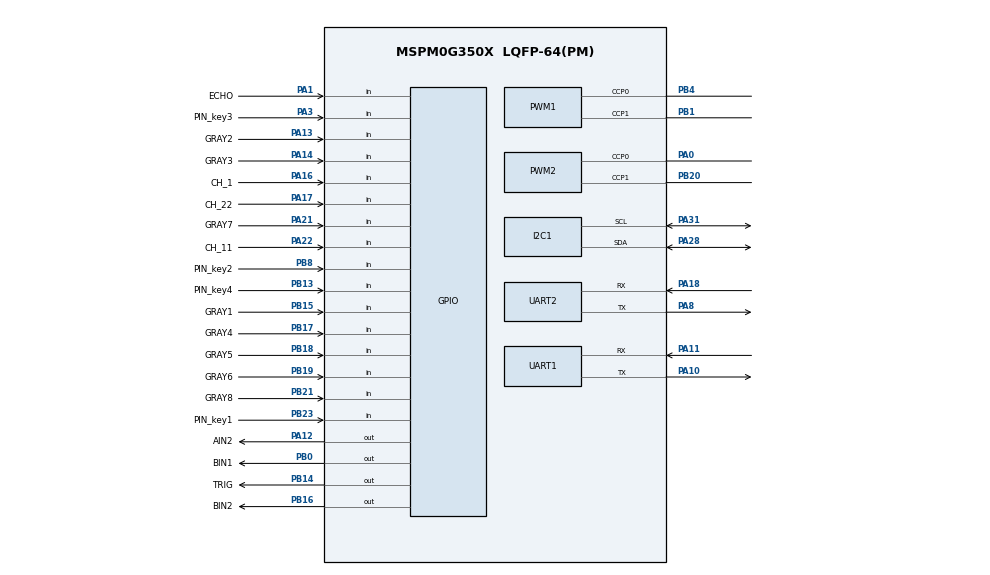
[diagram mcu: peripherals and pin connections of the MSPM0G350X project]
/**
 * @cliArgs --device "MSPM0G350X" --part "Default" --package "LQFP-64(PM)" --product "mspm0_sdk@2.11.00.07"
 * @versions {"tool":"1.26.2+4477"}
 */

/**
 * Import the modules used in this configuration.
 */
const GPIO   = scripting.addModule("/ti/driverlib/GPIO", {}, false);
const GPIO1  = GPIO.addInstance();
const GPIO2  = GPIO.addInstance();
const GPIO3  = GPIO.addInstance();
const GPIO4  = GPIO.addInstance();
const GPIO5  = GPIO.addInstance();
const PWM    = scripting.addModule("/ti/driverlib/PWM", {}, false);
const PWM1   = PWM.addInstance();
const PWM2   = PWM.addInstance();
const SYSCTL = scripting.addModule("/ti/driverlib/SYSCTL");
const TIMER  = scripting.addModule("/ti/driverlib/TIMER", {}, false);
const TIMER1 = TIMER.addInstance();
const TIMER2 = TIMER.addInstance();
const UART   = scripting.addModule("/ti/driverlib/UART", {}, false);
const UART1  = UART.addInstance();
const UART2  = UART.addInstance();

/**
 * Write custom configuration values to the imported modules.
 */
GPIO1.$name                                 = "MOTOR_DIR1";
GPIO1.associatedPins.create(4);
GPIO1.associatedPins[0].$name               = "AIN1";
GPIO1.associatedPins[0].subChanID           = 8;
GPIO1.associatedPins[0].assignedPort        = "PORTB";
GPIO1.associatedPins[0].assignedPin         = "9";
GPIO1.associatedPins[1].$name               = "AIN2";
GPIO1.associatedPins[1].assignedPort        = "PORTA";
GPIO1.associatedPins[1].assignedPin         = "12";
GPIO1.associatedPins[1].pin.$assign         = "PA12";
GPIO1.associatedPins[2].$name               = "CH_1";
GPIO1.associatedPins[2].direction           = "INPUT";
GPIO1.associatedPins[2].interruptEn         = true;
GPIO1.associatedPins[2].internalResistor    = "PULL_DOWN";
GPIO1.associatedPins[2].polarity            = "RISE_FALL";
GPIO1.associatedPins[2].assignedPortSegment = "Upper";
GPIO1.associatedPins[2].assignedPort        = "PORTA";
GPIO1.associatedPins[2].assignedPin         = "16";
GPIO1.associatedPins[2].pin.$assign         = "PA16";
GPIO1.associatedPins[3].$name               = "CH_2";
GPIO1.associatedPins[3].direction           = "INPUT";
GPIO1.associatedPins[3].internalResistor    = "PULL_DOWN";
GPIO1.associatedPins[3].assignedPort        = "PORTA";
GPIO1.associatedPins[3].interruptEn         = true;
GPIO1.associatedPins[3].polarity            = "RISE_FALL";
GPIO1.associatedPins[3].assignedPin         = "15";
GPIO1.associatedPins[3].assignedPortSegment = "Lower";

const Board = scripting.addModule("/ti/driverlib/Board", {}, false);

GPIO2.$name                                 = "MOTOR_DIR2";
GPIO2.associatedPins.create(4);
GPIO2.associatedPins[0].$name               = "BIN1";
GPIO2.associatedPins[0].assignedPort        = "PORTB";
GPIO2.associatedPins[0].assignedPin         = "00";
GPIO2.associatedPins[0].pin.$assign         = "PB0";
GPIO2.associatedPins[1].$name               = "BIN2";
GPIO2.associatedPins[1].assignedPin         = "16";
GPIO2.associatedPins[1].assignedPort        = "PORTB";
GPIO2.associatedPins[1].pin.$assign         = "PB16";
GPIO2.associatedPins[2].$name               = "CH_11";
GPIO2.associatedPins[2].direction           = "INPUT";
GPIO2.associatedPins[2].internalResistor    = "PULL_DOWN";
GPIO2.associatedPins[2].interruptEn         = true;
GPIO2.associatedPins[2].polarity            = "RISE_FALL";
GPIO2.associatedPins[2].assignedPort        = "PORTA";
GPIO2.associatedPins[2].assignedPortSegment = "Upper";
GPIO2.associatedPins[2].assignedPin         = "22";
GPIO2.associatedPins[2].pin.$assign         = "PA22";
GPIO2.associatedPins[3].$name               = "CH_22";
GPIO2.associatedPins[3].direction           = "INPUT";
GPIO2.associatedPins[3].internalResistor    = "PULL_DOWN";
GPIO2.associatedPins[3].assignedPort        = "PORTA";
GPIO2.associatedPins[3].assignedPortSegment = "Upper";
GPIO2.associatedPins[3].assignedPin         = "17";
GPIO2.associatedPins[3].polarity            = "RISE_FALL";
GPIO2.associatedPins[3].interruptEn         = true;
GPIO2.associatedPins[3].pin.$assign         = "PA17";

GPIO3.$name                         = "Grays";
GPIO3.associatedPins.create(8);
GPIO3.associatedPins[0].$name       = "GRAY1";
GPIO3.associatedPins[0].direction   = "INPUT";
GPIO3.associatedPins[0].pin.$assign = "PB15";
GPIO3.associatedPins[1].$name       = "GRAY2";
GPIO3.associatedPins[1].direction   = "INPUT";
GPIO3.associatedPins[1].pin.$assign = "PA13";
GPIO3.associatedPins[2].$name       = "GRAY3";
GPIO3.associatedPins[2].direction   = "INPUT";
GPIO3.associatedPins[2].pin.$assign = "PA14";
GPIO3.associatedPins[3].$name       = "GRAY4";
GPIO3.associatedPins[3].direction   = "INPUT";
GPIO3.associatedPins[3].pin.$assign = "PB17";
GPIO3.associatedPins[4].$name       = "GRAY5";
GPIO3.associatedPins[4].direction   = "INPUT";
GPIO3.associatedPins[4].pin.$assign = "PB18";
GPIO3.associatedPins[5].$name       = "GRAY6";
GPIO3.associatedPins[5].direction   = "INPUT";
GPIO3.associatedPins[5].pin.$assign = "PB19";
GPIO3.associatedPins[6].$name       = "GRAY7";
GPIO3.associatedPins[6].direction   = "INPUT";
GPIO3.associatedPins[6].pin.$assign = "PA21";
GPIO3.associatedPins[7].$name       = "GRAY8";
GPIO3.associatedPins[7].direction   = "INPUT";
GPIO3.associatedPins[7].pin.$assign = "PB21";

GPIO4.$name = "key";
GPIO4.associatedPins.create(4);
GPIO4.associatedPins[0].$name = "PIN_key1";
GPIO4.associatedPins[0].direction = "INPUT";
GPIO4.associatedPins[0].interruptEn = true;
GPIO4.associatedPins[0].polarity = "RISE_FALL";
GPIO4.associatedPins[0].assignedPort = "PORTB";
GPIO4.associatedPins[0].assignedPortSegment = "Upper";
GPIO4.associatedPins[0].assignedPin = "23";
GPIO4.associatedPins[0].internalResistor = "PULL_UP";
GPIO4.associatedPins[0].pin.$assign = "PB23";
GPIO4.associatedPins[1].$name = "PIN_key2";
GPIO4.associatedPins[1].direction = "INPUT";
GPIO4.associatedPins[1].assignedPort = "PORTB";
GPIO4.associatedPins[1].assignedPortSegment = "Lower";
GPIO4.associatedPins[1].assignedPin = "8";
GPIO4.associatedPins[1].internalResistor = "PULL_UP";
GPIO4.associatedPins[1].pin.$assign = "PB8";
GPIO4.associatedPins[2].$name = "PIN_key3";
GPIO4.associatedPins[2].direction = "INPUT";
GPIO4.associatedPins[2].assignedPort = "PORTA";
GPIO4.associatedPins[2].assignedPortSegment = "Lower";
GPIO4.associatedPins[2].assignedPin = "3";
GPIO4.associatedPins[2].internalResistor = "PULL_UP";
GPIO4.associatedPins[2].pin.$assign = "PA3";
GPIO4.associatedPins[3].$name = "PIN_key4";
GPIO4.associatedPins[3].direction = "INPUT";
GPIO4.associatedPins[3].assignedPort = "PORTB";
GPIO4.associatedPins[3].assignedPortSegment = "Lower";
GPIO4.associatedPins[3].assignedPin = "13";
GPIO4.associatedPins[3].internalResistor = "PULL_UP";
GPIO4.associatedPins[3].pin.$assign = "PB13";

PWM1.timerCount                         = 1600;
PWM1.timerStartTimer                    = true;
PWM1.$name                              = "PWM_motor";
PWM1.peripheral.ccp0Pin.$assign         = "PB4";
PWM1.peripheral.ccp1Pin.$assign         = "PB1";
PWM1.PWM_CHANNEL_0.$name                = "ti_driverlib_pwm_PWMTimerCC0";
PWM1.PWM_CHANNEL_0.dutyCycle            = 50;
PWM1.PWM_CHANNEL_1.$name                = "ti_driverlib_pwm_PWMTimerCC1";
PWM1.PWM_CHANNEL_1.dutyCycle            = 50;
PWM1.ccp0PinConfig.direction            = scripting.forceWrite("OUTPUT");
PWM1.ccp0PinConfig.hideOutputInversion  = scripting.forceWrite(false);
PWM1.ccp0PinConfig.onlyInternalResistor = scripting.forceWrite(false);
PWM1.ccp0PinConfig.passedPeripheralType = scripting.forceWrite("Digital");
PWM1.ccp0PinConfig.$name                = "ti_driverlib_gpio_GPIOPinGeneric0";
PWM1.ccp0PinConfig.enableConfig         = true;
PWM1.ccp1PinConfig.direction            = scripting.forceWrite("OUTPUT");
PWM1.ccp1PinConfig.hideOutputInversion  = scripting.forceWrite(false);
PWM1.ccp1PinConfig.onlyInternalResistor = scripting.forceWrite(false);
PWM1.ccp1PinConfig.passedPeripheralType = scripting.forceWrite("Digital");
PWM1.ccp1PinConfig.$name                = "ti_driverlib_gpio_GPIOPinGeneric1";
PWM1.ccp1PinConfig.enableConfig         = true;

PWM2.$name                              = "PWM_servo";
PWM2.clockDivider                       = 8;
PWM2.clockPrescale                      = 4;
PWM2.timerCount                         = 20000;
PWM2.peripheral.ccp0Pin.$assign         = "PA0";
PWM2.peripheral.ccp1Pin.$assign         = "PB20";
PWM2.PWM_CHANNEL_0.$name                = "ti_driverlib_pwm_PWMTimerCC2";
PWM2.PWM_CHANNEL_0.ccValue              = 18500;
PWM2.PWM_CHANNEL_1.$name                = "ti_driverlib_pwm_PWMTimerCC3";
PWM2.PWM_CHANNEL_1.ccValue              = 18500;
PWM2.ccp0PinConfig.direction            = scripting.forceWrite("OUTPUT");
PWM2.ccp0PinConfig.hideOutputInversion  = scripting.forceWrite(false);
PWM2.ccp0PinConfig.onlyInternalResistor = scripting.forceWrite(false);
PWM2.ccp0PinConfig.passedPeripheralType = scripting.forceWrite("Digital");
PWM2.ccp0PinConfig.$name                = "ti_driverlib_gpio_GPIOPinGeneric2";
PWM2.ccp1PinConfig.direction            = scripting.forceWrite("OUTPUT");
PWM2.ccp1PinConfig.hideOutputInversion  = scripting.forceWrite(false);
PWM2.ccp1PinConfig.onlyInternalResistor = scripting.forceWrite(false);
PWM2.ccp1PinConfig.passedPeripheralType = scripting.forceWrite("Digital");
PWM2.ccp1PinConfig.$name                = "ti_driverlib_gpio_GPIOPinGeneric3";

/**
 * Five flame-sensor analog outputs: ADC0 channels 0..4 -> MEM0..MEM4.
 * Software-triggered single sequence; MEM4 result marks completion.
 * VDDA must actually be 3.3 V; the voltage metadata does not set supply voltage.
 * 40 us acquisition is an initial setting; verify against sensor output impedance.
 */
const ADC12 = scripting.addModule("/ti/driverlib/ADC12", {}, false);
const ADC121 = ADC12.addInstance();
ADC121.$name = "fire_adc";
ADC121.peripheral.$assign = "ADC0";
ADC121.sampClkSrc = "DL_ADC12_CLOCK_ULPCLK";
ADC121.sampClkDiv = "DL_ADC12_CLOCK_DIVIDE_8";
ADC121.powerDownMode = "DL_ADC12_POWER_DOWN_MODE_MANUAL";
ADC121.resolution = "DL_ADC12_SAMP_CONV_RES_12_BIT";
ADC121.samplingOperationMode = "sequence";
ADC121.startAdd = 0;
ADC121.endAdd = 4;
ADC121.repeatMode = false;
ADC121.sampleTime0 = "40 us";
ADC121.enabledInterrupts = ["DL_ADC12_INTERRUPT_MEM4_RESULT_LOADED"];
ADC121.adcMem0_name = "fire0";
ADC121.adcMem1_name = "fire1";
ADC121.adcMem2_name = "fire2";
ADC121.adcMem3_name = "fire3";
ADC121.adcMem4_name = "fire4";
ADC121.adcMem0chansel = "DL_ADC12_INPUT_CHAN_0";
ADC121.adcMem1chansel = "DL_ADC12_INPUT_CHAN_1";
ADC121.adcMem2chansel = "DL_ADC12_INPUT_CHAN_2";
ADC121.adcMem3chansel = "DL_ADC12_INPUT_CHAN_3";
ADC121.adcMem4chansel = "DL_ADC12_INPUT_CHAN_4";
ADC121.adcMem0vref = "VDDA";
ADC121.adcMem1vref = "VDDA";
ADC121.adcMem2vref = "VDDA";
ADC121.adcMem3vref = "VDDA";
ADC121.adcMem4vref = "VDDA";
ADC121.peripheral.adcPin0.$assign = "PA27";
ADC121.peripheral.adcPin1.$assign = "PA26";
ADC121.peripheral.adcPin2.$assign = "PA25";
ADC121.peripheral.adcPin3.$assign = "PA24";
ADC121.peripheral.adcPin4.$assign = "PB25";

/**
 * OLED I2C controller: external SDA/SCL pull-ups to 3.3 V required.
 * Start at standard-mode 100 kHz; select a faster rate only after checking the panel.
 */
const I2C = scripting.addModule("/ti/driverlib/I2C", {}, false);
const I2C1 = I2C.addInstance();
I2C1.$name = "I2C_oled";
I2C1.basicEnableController = true;
I2C1.basicEnableTarget = false;
I2C1.basicControllerBusSpeed = 100000;
I2C1.peripheral.$assign = "I2C0";
I2C1.peripheral.sdaPin.$assign = "PA28";
I2C1.peripheral.sclPin.$assign = "PA31";
I2C1.sdaPinConfig.$name = "I2C_oled_SDA";
I2C1.sclPinConfig.$name = "I2C_oled_SCL";

SYSCTL.forceDefaultClkConfig = true;

GPIO5.$name = "HCSR04";
GPIO5.associatedPins.create(2);
GPIO5.associatedPins[0].$name = "ECHO";
GPIO5.associatedPins[0].direction = "INPUT";
GPIO5.associatedPins[0].interruptEn = true;
GPIO5.associatedPins[0].polarity = "RISE_FALL";
GPIO5.associatedPins[0].pin.$assign = "PA1";
GPIO5.associatedPins[1].$name = "TRIG";
GPIO5.associatedPins[1].pin.$assign = "PB14";

TIMER2.$name = "hcsr04_timer";
TIMER2.timerClkDiv = 8;
TIMER2.timerClkPrescale = 8;
TIMER2.timerPeriod = "100 ms";
TIMER2.timerMode = "PERIODIC";
TIMER2.interrupts = ["ZERO"];
TIMER2.peripheral.$assign = "TIMG6";

UART2.$name = "UART_JY901P";
UART2.targetBaudRate = 9600;
UART2.peripheral.$assign = "UART1";
UART2.peripheral.rxPin.$assign = "PA18";
UART2.peripheral.txPin.$assign = "PA8";
UART2.txPinConfig.$name = "ti_driverlib_gpio_GPIOPinGeneric14";
UART2.rxPinConfig.$name = "ti_driverlib_gpio_GPIOPinGeneric15";

TIMER1.$name              = "pid_timer";
TIMER1.timerClkDiv        = 8;
TIMER1.timerClkPrescale   = 4;
TIMER1.timerPeriod        = "10 ms";
TIMER1.timerMode          = "PERIODIC";
TIMER1.interrupts         = ["ZERO"];
TIMER1.peripheral.$assign = "TIMG0";

UART1.$name                    = "UART_0";
UART1.targetBaudRate           = 115200;
UART1.peripheral.$assign       = "UART0";
UART1.peripheral.rxPin.$assign = "PA11";
UART1.peripheral.txPin.$assign = "PA10";
UART1.txPinConfig.$name        = "ti_driverlib_gpio_GPIOPinGeneric4";
UART1.rxPinConfig.$name        = "ti_driverlib_gpio_GPIOPinGeneric5";

/**
 * Pinmux solution for unlocked pins/peripherals. This ensures that minor changes to the automatic solver in a future
 * version of the tool will not impact the pinmux you originally saw.  These lines can be completely deleted in order to
 * re-solve from scratch.
 */
GPIO1.associatedPins[0].pin.$suggestSolution = "PB9";
GPIO1.associatedPins[3].pin.$suggestSolution = "PA15";
PWM1.peripheral.$suggestSolution             = "TIMA1";
PWM2.peripheral.$suggestSolution             = "TIMA0";
SYSCTL.peripheral.$suggestSolution           = "SYSCTL";
